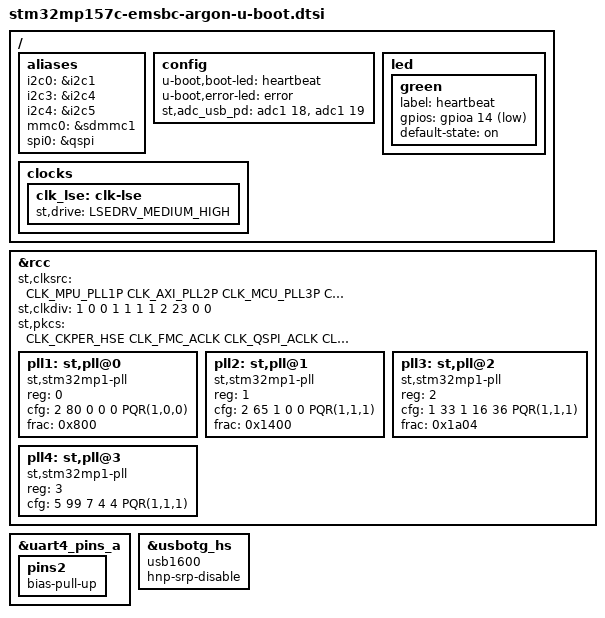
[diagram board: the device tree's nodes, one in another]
// SPDX-License-Identifier: (GPL-2.0+ OR BSD-3-Clause)
/*
 * Copyright (C) emtrion GmbH 2021 - All Rights Reserved
 */

#include <dt-bindings/clock/stm32mp1-clksrc.h>
#include "stm32mp15-u-boot.dtsi"
#include "stm32mp15-ddr3-1x4Gb-1066-binG.dtsi"

/ {
	aliases {
		i2c0 = &i2c1;
		i2c3 = &i2c4;
		i2c4 = &i2c5;
		mmc0 = &sdmmc1;
		spi0 = &qspi;
	};
	config {
		u-boot,boot-led = "heartbeat";
		u-boot,error-led = "error";
		st,adc_usb_pd = <&adc1 18>, <&adc1 19>;
	};
	led {
		green {
			label = "heartbeat";
			gpios = <&gpioa 14 GPIO_ACTIVE_LOW>;
			default-state = "on";
			status = "okay";
		};
	};
	clocks {
		clk_lse: clk-lse {
			st,drive = <LSEDRV_MEDIUM_HIGH>;
		};
	};
};

&rcc {
	st,clksrc = <
		CLK_MPU_PLL1P
		CLK_AXI_PLL2P
		CLK_MCU_PLL3P
		CLK_PLL12_HSE
		CLK_PLL3_HSE
		CLK_PLL4_HSE
		CLK_RTC_LSE
		CLK_MCO1_DISABLED
		CLK_MCO2_DISABLED
	>;

	st,clkdiv = <
		1 /*MPU*/
		0 /*AXI*/
		0 /*MCU*/
		1 /*APB1*/
		1 /*APB2*/
		1 /*APB3*/
		1 /*APB4*/
		2 /*APB5*/
		23 /*RTC*/
		0 /*MCO1*/
		0 /*MCO2*/
	>;

	st,pkcs = <
		CLK_CKPER_HSE
		CLK_FMC_ACLK
		CLK_QSPI_ACLK
		CLK_ETH_PLL4P
		CLK_SDMMC12_PLL4P
		CLK_DSI_DSIPLL
		CLK_STGEN_HSE
		CLK_USBPHY_HSE
		CLK_SPI2S1_PLL4P
		CLK_SPI2S23_PLL3Q
		CLK_SPI45_HSI
		CLK_SPI6_HSI
		CLK_I2C46_HSI
		CLK_SDMMC3_PLL4P
		CLK_USBO_USBPHY
		CLK_ADC_CKPER
		CLK_CEC_LSE
		CLK_I2C12_HSI
		CLK_I2C35_HSI
		CLK_UART1_HSI
		CLK_UART24_HSI
		CLK_UART35_HSI
		CLK_UART6_HSI
		CLK_UART78_HSI
		CLK_SPDIF_PLL4P
		CLK_FDCAN_PLL4R
		CLK_SAI1_PLL3Q
		CLK_SAI2_PLL3Q
		CLK_SAI3_PLL3Q
		CLK_SAI4_PLL3Q
		CLK_RNG1_LSI
		CLK_RNG2_LSI
		CLK_LPTIM1_PCLK1
		CLK_LPTIM23_PCLK3
		CLK_LPTIM45_LSE
	>;

	/* VCO = 1300.0 MHz => P = 650 (CPU) */
	pll1: st,pll@0 {
		compatible = "st,stm32mp1-pll";
		reg = <0>;
		cfg = < 2 80 0 0 0 PQR(1,0,0) >;
		frac = < 0x800 >;
	};

	/* VCO = 1066.0 MHz => P = 266 (AXI), Q = 533 (GPU), R = 533 (DDR) */
	pll2: st,pll@1 {
		compatible = "st,stm32mp1-pll";
		reg = <1>;
		cfg = < 2 65 1 0 0 PQR(1,1,1) >;
		frac = < 0x1400 >;
	};

	/* VCO = 417.8 MHz => P = 209, Q = 24, R = 11 */
	pll3: st,pll@2 {
		compatible = "st,stm32mp1-pll";
		reg = <2>;
		cfg = < 1 33 1 16 36 PQR(1,1,1) >;
		frac = < 0x1a04 >;
	};

	/* P = 50, Q = 80, R = 80 */
	pll4: st,pll@3 {
		compatible = "st,stm32mp1-pll";
		reg = <3>;
		cfg = < 5 99 7 4 4 PQR(1,1,1) >;
	};
};

&uart4_pins_a {
	pins2 {
		/* pull-up on rx to avoid floating level */
		bias-pull-up;
	};
};

&usbotg_hs {
	usb1600;
	hnp-srp-disable;
};
